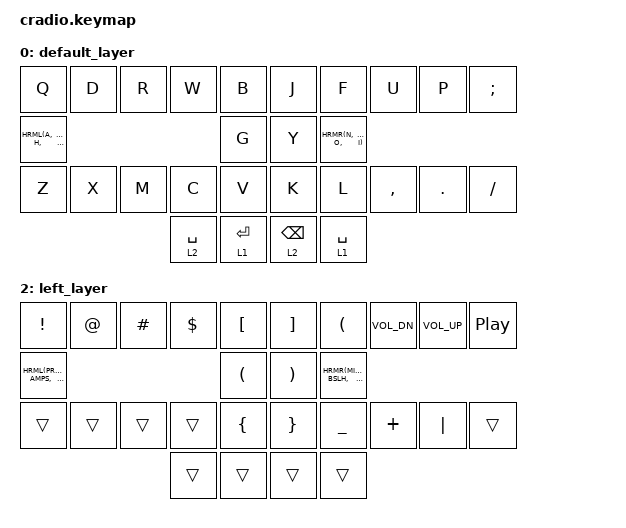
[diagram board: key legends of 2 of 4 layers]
// Copyright (c) 2022 The ZMK Contributors
// SPDX-License-Identifier: MIT

#include <behaviors.dtsi>
#include <dt-bindings/zmk/keys.h>
#include <dt-bindings/zmk/bt.h>

// Home row mods macro
#define HRML(k1,k2,k3,k4) &ht LSHFT k1  &ht LCTRL k2  &ht LALT k3  &ht LGUI k4
#define HRMR(k1,k2,k3,k4) &ht RGUI k1  &ht RALT k2  &ht RCTRL k3  &ht RSHFT k4

/ {
    behaviors {
        ht: hold_tap {
            compatible = "zmk,behavior-hold-tap";
            #binding-cells = <2>;
            flavor = "balanced";
            tapping-term-ms = <220>;
            quick-tap-ms = <150>;
            require-prior-idle-ms = <0>;
            bindings = <&kp>, <&kp>;
        };
    };

    conditional_layers {
        compatible = "zmk,conditional-layers";
        tri_layer {
            if-layers = <1 2>;
            then-layer = <3>;
        };
    };

    keymap {
        compatible = "zmk,keymap";
        default_layer {
            bindings = <
        //╭──────────┬──────────┬──────────┬──────────┬──────────╮   ╭──────────┬──────────┬──────────┬──────────┬──────────╮
        //│  Q       │  D       │  R       │  W       │  B       │   │  J       │  F       │  U       │  P       │  ;       │
            &kp Q      &kp D      &kp R      &kp W      &kp B          &kp J      &kp F      &kp U      &kp P      &kp SEMI
        //├──────────┼──────────┼──────────┼──────────┼──────────┤   ├──────────┼──────────┼──────────┼──────────┼──────────┤
        //│  A       │  S       │  H       │  T       │  G       │   │  Y       │  N       │  E       │  O       │  I       │
            HRML(A,        S,         H,         T)     &kp G          &kp Y      HRMR(N,        E,         O,        I)
        //├──────────┼──────────┼──────────┼──────────┼──────────┤   ├──────────┼──────────┼──────────┼──────────┼──────────┤
        //│  Z       │  X       │  M       │  C       │  V       │   │  K       │  L       │ , <      │ . >      │ / ?      │
            &kp Z      &kp X      &kp M      &kp C      &kp V          &kp K      &kp L      &kp COMMA  &kp DOT    &kp FSLH
        //╰──────────┴──────────┴──────────┼──────────┼──────────┤   ├──────────┼──────────┼──────────┴──────────┴──────────╯
                                            &lt 2 SPACE &lt 1 ENTER   &lt 2 BSPC  &lt 1 SPACE
        //                                 ╰──────────┴──────────╯   ╰──────────┴──────────╯
            >;
        };

        right_layer {
            bindings = <
        //╭──────────┬──────────┬──────────┬──────────┬──────────╮   ╭──────────┬──────────┬──────────┬──────────┬──────────╮
        //│ ESCAPE   │  1       │  2       │  3       │  COPY    │   │shortcat  │ PAGE DN  │  UP      │ PAGE UP  │  :       │
            &kp ESC    &kp N1     &kp N2     &kp N3     &kp LG(C)     &kp LG(LA(LS(S)))   &kp PG_DN  &kp UARW    &kp PG_UP    &kp COLON
        //├──────────┼──────────┼──────────┼──────────┼──────────┤   ├──────────┼──────────┼──────────┼──────────┼──────────┤
        //│ TAB      │  4       │  5       │  6       │  PASTE   │   │copy hist │ LEFT     │ DOWN     │ RIGHT    │  ' "     │
            HRML(TAB,   N4,        N5,        N6)       &kp LG(V)     &kp LG(LA(C)) HRMR(LARW,  DARW,      RARW,   SQT)
        //├──────────┼──────────┼──────────┼──────────┼──────────┤   ├──────────┼──────────┼──────────┼──────────┼──────────┤
        //│ CAPS     │  7       │  8       │  9       │  0       │   │          │          │          │          │          │
           &caps_word  &kp N7     &kp N8     &kp N9     &kp N0         &trans     &trans     &trans     &trans     &trans
        //╰──────────┴──────────┴──────────┼──────────┼──────────┤   ├──────────┼──────────┼──────────┴──────────┴──────────╯
                                             &trans     &kp ESC        &trans     &trans
        //                                 ╰──────────┴──────────╯   ╰──────────┴──────────╯
            >;
        };

        left_layer {
            bindings = <
        //╭──────────┬──────────┬──────────┬──────────┬──────────╮   ╭──────────┬──────────┬──────────┬──────────┬──────────╮
        //│ !        │  @       │  #       │  $       │  [       │   │  ]       │  !       │ VOL_DWN  │ VOL_UP   │PLAY/PAUSE│
          &kp EXCL    &kp AT   &kp HASH   &kp DLLR   &kp LBKT         &kp RBKT  &kp LPAR   &kp C_VOL_DN &kp C_VOL_UP  &kp C_PP
        //├──────────┼──────────┼──────────┼──────────┼──────────┤   ├──────────┼──────────┼──────────┼──────────┼──────────┤
        //│  %       │  ^       │  &       │  *       │  (       │   │  )       │  -       │  =       │  \       │  `       │
          HRML(PRCNT,   CARET,       AMPS,      ASTRK)   &kp LPAR      &kp RPAR  HRMR(MINUS,  EQUAL,    BSLH,     GRAVE)
        //├──────────┼──────────┼──────────┼──────────┼──────────┤   ├──────────┼──────────┼──────────┼──────────┼──────────┤
        //│          │          │          │          │  {       │   │  }       │  _       │  +       │  │       │          │
          &trans      &trans       &trans     &trans     &kp LBRC      &kp RBRC   &kp UNDER  &kp PLUS   &kp PIPE   &trans
        //╰──────────┴──────────┴──────────┼──────────┼──────────┤   ├──────────┼──────────┼──────────┴──────────┴──────────╯
                                             &trans     &trans         &trans     &trans
        //                                 ╰──────────┴──────────╯   ╰──────────┴──────────╯
            >;
        };

        tri_layer {
            bindings = <
        //╭──────────┬──────────┬──────────┬──────────┬──────────╮   ╭──────────┬──────────┬──────────┬──────────┬──────────╮
        //│ `        │          │          │PROFILE 0 │          │   │          │          │          │          │  RESET   │
           &kp GRAVE  &trans     &trans  &bt BT_SEL 0 &trans          &trans     &trans     &trans     &trans    &sys_reset
        //├──────────┼──────────┼──────────┼──────────┼──────────┤   ├──────────┼──────────┼──────────┼──────────┼──────────┤
        //│          │          │          │PROFILE 1 │ <        │   │ >        │          │          │          │BOOTLOADER│
          &trans      &trans     &trans  &bt BT_SEL 1  &kp LT        &kp GT     &trans     &trans     &trans    &bootloader
        //├──────────┼──────────┼──────────┼──────────┼──────────┤   ├──────────┼──────────┼──────────┼──────────┼──────────┤
        //│          │          │          │ CLEAR BT │          │   │          │          │          │          │ CLEAR BT │
            &trans     &trans     &trans    &bt BT_CLR &trans          &trans     &trans     &trans     &trans     &bt BT_CLR
        //╰──────────┴──────────┴──────────┼──────────┼──────────┤   ├──────────┼──────────┼──────────┴──────────┴──────────╯
                                             &trans     &trans         &trans     &trans
        //                                 ╰──────────┴──────────╯   ╰──────────┴──────────╯
            >;
        };
    };
};
